# c71_SEv2 register map
Vendor: Texas Instruments
Peripheral module from a debugger description file (folder C71).
Registers are 64-bit, access not given, no defined reset value unless marked. A register's access mark holds for its fields unless they carry their own. Offsets are as the file gives them; lines under a group give offsets from that group; [hi:lo] are bit positions; {n}, {i} and the like mark numbered series; 'fields as' and 'values as' point back to an identical list; <NAME> marks a mode.

## SE — Streaming Engine
0x300 SE0_PID ro reset 0x60E00800 — Stream 0 PID Register
  [31:0] REV_ID — PID Revision
0x301 SE0_FAR access per field reset 0x0 — Stream 0 Fail Address Register
  [48:7] FAR rw
0x302 SE0_FSR access per field reset 0x0 — Stream 0 Fail Status Register
  [12:0] FSR rw
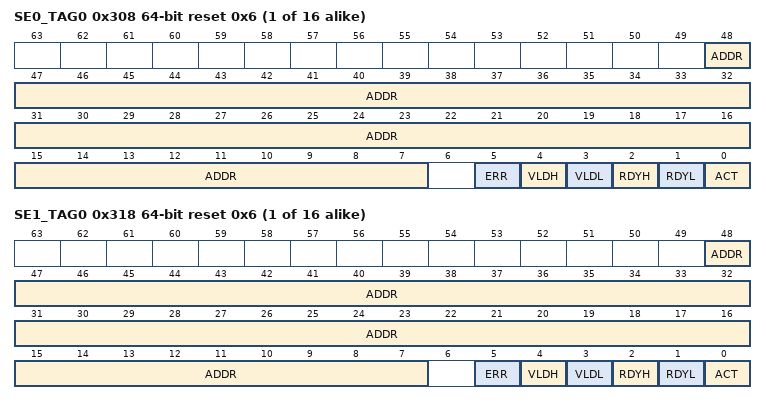
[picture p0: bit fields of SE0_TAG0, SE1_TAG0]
{0x308+0x100000*i} SE0_TAG{i} ro reset 0x6 (i=0..15) — Stream 0 Tag Data and Metadata Register Index {i}
  [48:7] ADDR — Reserved
  [5] ERR — Error Bit
  [4] VLDH — High Valid Bit
  [3] VLDL — Low Valid Bit
  [2] RDYH — High Ready Bit
  [1] RDYL — Low Ready Bit
  [0] ACT — Active Bit
0x309 SE0_ICNT0 — Early Remaining Iteration Count for Loop Level 0 (innermost loop)
{0x30A+0x100000*i} SE0_DIM{i} ro reset 0x0 (i=0..4) — Stream 0 Dimension Register Index {i}
  [31:0] DIM
{0x30B+0x100000*i} SE0_ADDR{i} (i=0..5) — Early Address for hardware dimension {i}
0x30C SE0_STATUS0 ro reset 0x0 — Stream 0 Status and Flag Register
  [63:0] FLAG
0x30D SE0_SIDEBAND0 — SE0 Sideband Register User Fill Value
0x310 SE1_PID ro reset 0x60E00800 — Stream 1 PID Register
  [31:0] REV_ID — PID Revision
0x311 SE1_FAR access per field reset 0x0 — Stream 1 Fail Address Register
  [48:7] FAR rw
0x312 SE1_FSR access per field reset 0x0 — Stream 1 Fail Status Register
  [12:0] FSR rw
{0x318+0x100000*i} SE1_TAG{i} ro reset 0x6 (i=0..15) — Stream 1 Tag Data and Metadata Register Index {i}
  fields as SE0_TAG0
0x319 SE1_ICNT0 — Early Remaining Iteration Count for Loop Level 0 (innermost loop)
{0x31A+0x100000*i} SE1_DIM{i} ro reset 0x0 (i=0..4) — Stream 1 Dimension Register Index {i}
  [31:0] DIM
{0x31B+0x100000*i} SE1_ADDR{i} (i=0..5) — Early Address for hardware dimension {i}
0x31C SE1_STATUS0 ro reset 0x0 — Stream 1 Status and Flag Register
  [63:0] FLAG
0x31D SE1_SIDEBAND0 — SE1 Sideband Register User Fill Value
0x320 SE2_PID ro reset 0x0 — Stream 2 PID Register
0x330 SE3_PID ro reset 0x0 — Stream 3 PID Register
{0x309+0x100000*i} SE0_ICNT{i} (i=1..4) — Early Remaining Iteration Count for Loop Level {i}
0x10030C SE0_STATUS1 — Stream 0 User Fill Value Snapshot
{0x319+0x100000*i} SE1_ICNT{i} (i=1..4) — Early Remaining Iteration Count for Loop Level {i}
0x10031C SE1_STATUS1 — Stream 1 User Fill Value Snapshot
0x500309 SE0_ICNT5 — Early Remaining Iteration Count for Loop Level 5 (outermost loop)
0x500319 SE1_ICNT5 — Early Remaining Iteration Count for Loop Level 5 (outermost loop)
0x600309 SE0_ICNT6 — Early Remaining Iteration Count for DECDIM1_WIDTH
0x600319 SE1_ICNT6 — Early Remaining Iteration Count for DECDIM1_WIDTH
0x700309 SE0_ICNT7 — Early Remaining Iteration Count for DECDIM2_WIDTH
0x700319 SE1_ICNT7 — Early Remaining Iteration Count for DECDIM2_WIDTH
0x800309 SE0_ICNT8 — Early Remaining Iteration Count for LEZR_CNT
{0x30B+0x100000*i} SE0_ADDR{i} (i=8..13) — Late Address for hardware dimension {i-8}
0x800319 SE1_ICNT8 — Early Remaining Iteration Count for LEZR_CNT
{0x31B+0x100000*i} SE1_ADDR{i} (i=8..13) — Late Address for hardware dimension {i-8}
0xA00309 SE0_ICNT10 — Late Remaining Iteration Count for Loop Level 0 (innermost loop)
0xA00319 SE1_ICNT10 — Late Remaining Iteration Count for Loop Level 0 (innermost loop)
{0x309+0x100000*i} SE0_ICNT{i} (i=11..14) — Late Remaining Iteration Count for Loop Level {i-10}
{0x319+0x100000*i} SE1_ICNT{i} (i=11..14) — Late Remaining Iteration Count for Loop Level {i-10}
0xF00309 SE0_ICNT15 — Late Remaining Iteration Count for Loop Level 5 (outermost loop)
0xF00319 SE1_ICNT15 — Late Remaining Iteration Count for Loop Level 5 (outermost loop)
0x1000309 SE0_ICNT16 — Late Remaining Iteration Count for DECDIM1_WIDTH
0x1000319 SE1_ICNT16 — Late Remaining Iteration Count for DECDIM1_WIDTH
0x1100309 SE0_ICNT17 — Late Remaining Iteration Count for DECDIM2_WIDTH
0x1100319 SE1_ICNT17 — Late Remaining Iteration Count for DECDIM2_WIDTH
0x1200309 SE0_ICNT18 — Late Remaining Iteration Count for LEZR_CNT
0x1200319 SE1_ICNT18 — Late Remaining Iteration Count for LEZR_CNT
{0x309+0x100000*i} SE0_ICNT{i} (i=20..25) — ICNT{i-20} from template
{0x319+0x100000*i} SE1_ICNT{i} (i=20..25) — ICNT{i-20} from template
0x1A00309 SE0_ICNT26 — DECDIM1_WIDTH from template
0x1A00319 SE1_ICNT26 — DECDIM1_WIDTH from template
0x1B00309 SE0_ICNT27 — DECDIM2_WIDTH from template
0x1B00319 SE1_ICNT27 — DECDIM2_WIDTH from template
0x1C00309 SE0_ICNT28 — LEZR_CNT from template
0x1C00319 SE1_ICNT28 — LEZR_CNT from template
0x1E00309 SE0_ICNT30 — Early Remaining Iteration Count for INVERSE_DECDIM1_WIDTH
0x1E00319 SE1_ICNT30 — Early Remaining Iteration Count for INVERSE_DECDIM1_WIDTH
0x1F00309 SE0_ICNT31 — Early Remaining Iteration Count for INVERSE_DECDIM2_WIDTH
0x1F00319 SE1_ICNT31 — Early Remaining Iteration Count for INVERSE_DECDIM2_WIDTH
0x2000309 SE0_ICNT32 — Early Row Remaining
0x2000319 SE1_ICNT32 — Early Row Remaining
0x2100309 SE0_ICNT33 — Early LPAD Width
0x2100319 SE1_ICNT33 — Early LPAD Width
0x2200309 SE0_ICNT34 — Early RPAD Width
0x2200319 SE1_ICNT34 — Early RPAD Width
0x2800309 SE0_ICNT40 — Late Remaining Iteration Count for INVERSE_DECDIM1_WIDTH
0x2800319 SE1_ICNT40 — Late Remaining Iteration Count for INVERSE_DECDIM1_WIDTH
0x2900309 SE0_ICNT41 — Late Remaining Iteration Count for INVERSE_DECDIM2_WIDTH
0x2900319 SE1_ICNT41 — Late Remaining Iteration Count for INVERSE_DECDIM2_WIDTH
0x2A00309 SE0_ICNT42 — Late Row Remaining
0x2A00319 SE1_ICNT42 — Late Row Remaining
0x2B00309 SE0_ICNT43 — Late LPAD Width
0x2B00319 SE1_ICNT43 — Late LPAD Width
0x2C00309 SE0_ICNT44 — Late RPAD Width
0x2C00319 SE1_ICNT44 — Late RPAD Width
0x3200309 SE0_ICNT50 — INVERSE_DECDIM1_WIDTH
0x3200319 SE1_ICNT50 — INVERSE_DECDIM1_WIDTH
0x3300309 SE0_ICNT51 — INVERSE_DECDIM2_WIDTH
0x3300319 SE1_ICNT51 — INVERSE_DECDIM2_WIDTH
0x3400309 SE0_ICNT52 — Starting Offset
0x3400319 SE1_ICNT52 — Starting Offset
0x3500309 SE0_ICNT53 — LPAD Width
0x3500319 SE1_ICNT53 — LPAD Width
0x3600309 SE0_ICNT54 — RPAD Width
0x3600319 SE1_ICNT54 — RPAD Width
